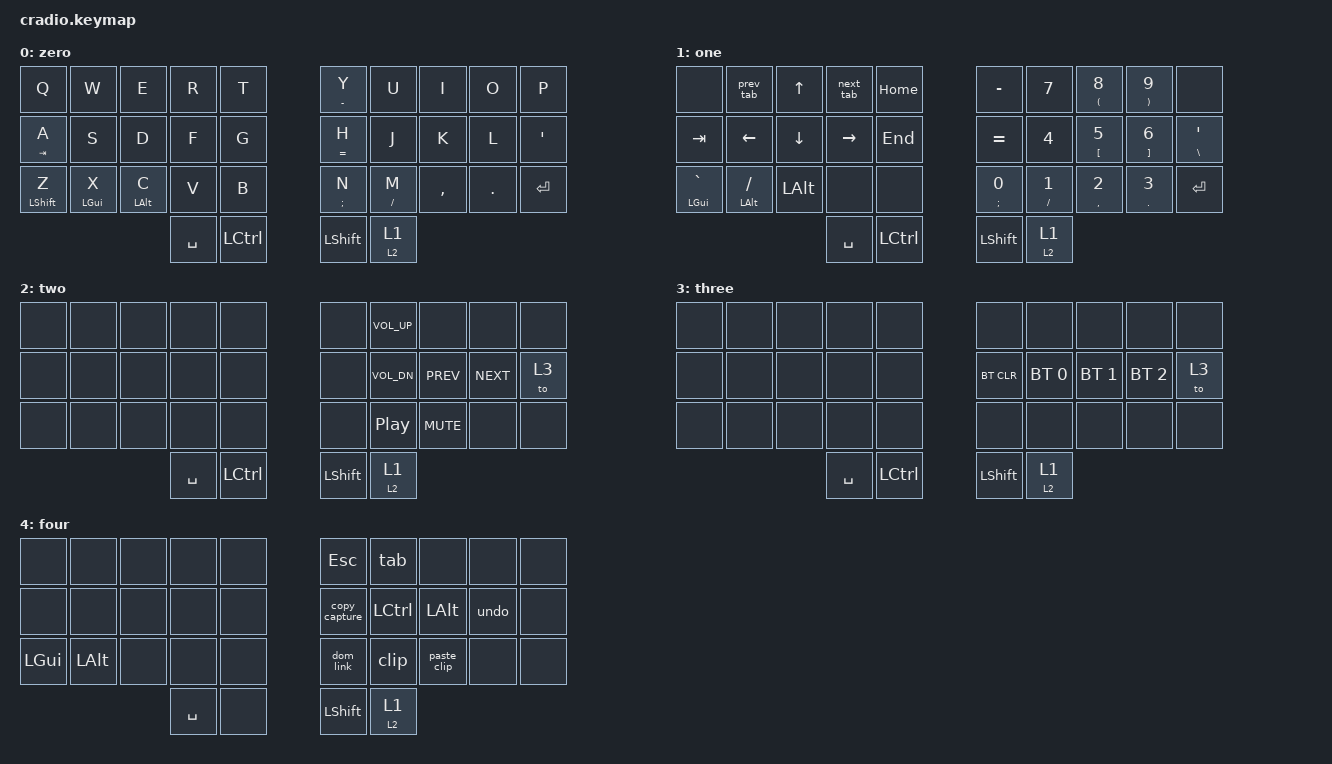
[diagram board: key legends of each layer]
/*
 * Copyright (c) 2020 The ZMK Contributors
 *
 * SPDX-License-Identifier: MIT
 */

#include <behaviors.dtsi>
#include <dt-bindings/zmk/keys.h>
#include <dt-bindings/zmk/bt.h>

&mt {
  //  flavor = "tap-preferred";
   // tapping_term_ms = <50>;
};

/ {    
        behaviors {
                to_kp: behavior_kp_to {
                compatible = "zmk,behavior-hold-tap";
                label = "kp_to";
                #binding-cells = <2>;
                flavor = "hold-preferred";
                tapping-term-ms = <750>;
                bindings = <&to>, <&kp>;
                };

                to_to: behavior_to_to {
                compatible = "zmk,behavior-hold-tap";
                label = "to_to";
                #binding-cells = <2>;
                flavor = "hold-preferred";
                tapping-term-ms = <750>;
                bindings = <&to>, <&to>;
                };

                tab: behavior_tab {
                compatible = "zmk,behavior-hold-tap";
                label = "tab";
                #binding-cells = <2>;
                flavor = "hold-preferred";
                tapping_term_ms = <500>;
                bindings = <&next_tab>, <&close_tab>;
                };

                clip: behavior_clip {
                compatible = "zmk,behavior-hold-tap";
                label = "clip";
                #binding-cells = <2>;
                flavor = "hold-preferred";
                tapping_term_ms = <100>;
                bindings = <&cut_clip>, <&copy_clip>;
                };
        };
    
        combos {
                compatible = "zmk,combos";
                combo_esc {
                        timeout-ms = <100>;
                        key-positions = <0 1>;
                        bindings = <&kp ESC>;
                };
                
                combo_bspc {
                        timeout-ms = <100>;
                        key-positions = <17 18>;
                        bindings = <&kp BSPC>;
                };
                
                combo_zero {
                        timeout-ms = <100>;
                        key-positions = <6 7>;
                        bindings = <&to 0>;
                };

                combo_five {
                        timeout-ms = <100>;
                        key-positions = <16 17>;
                        bindings = <&to 5>;
                };

                combo_four {
                        timeout-ms = <100>;
                        key-positions = <15 17>;
                        bindings = <&to 4>;
                };
        };

        macros {
                ZMK_MACRO(copy_capture,
                bindings = 
                <&macro_press &kp LSHIFT &kp LGUI>
                , <&macro_tap  &kp S>
                , <&macro_release &kp LSHIFT &kp LGUI>
                ;
                )

                ZMK_MACRO(next_tab,
                bindings = 
                <&macro_press &kp LCTL>
                , <&macro_tap  &kp TAB>
                , <&macro_release &kp LCTL>
                ;
                )

                ZMK_MACRO(prev_tab,
                bindings = 
                <&macro_press &kp LCTL &kp LSHIFT>
                , <&macro_tap  &kp TAB>
                , <&macro_release &kp LCTL &kp LSHIFT>
                ;
                )

                ZMK_MACRO(close_tab,
                bindings = 
                <&macro_press &kp LCTL>
                , <&macro_tap  &kp W>
                , <&macro_release &kp LCTL>
                ;
                )

                ZMK_MACRO(copy_clip,
                bindings = 
                <&macro_press &kp LCTL>
                , <&macro_tap  &kp C>
                , <&macro_release &kp LCTL>
                ;
                )

                ZMK_MACRO(cut_clip,
                bindings = 
                <&macro_press &kp LCTL>
                , <&macro_tap  &kp X>
                , <&macro_release &kp LCTL>
                ;
                )

                ZMK_MACRO(paste_clip,
                bindings = 
                <&macro_press &kp LCTL>
                , <&macro_tap  &kp V>
                , <&macro_release &kp LCTL>
                ;
                )

                ZMK_MACRO(dom_link,
                bindings = 
                <&macro_press &kp LCTL>
                , <&macro_tap  &kp L>
                , <&macro_release &kp LCTL>
                ;
                )

                ZMK_MACRO(undo,
                bindings = 
                <&macro_press &kp LCTL>
                , <&macro_tap  &kp Z>
                , <&macro_release &kp LCTL>
                ;
                )
        };

        keymap {
                compatible = "zmk,keymap";
                
       		zero {
	bindings = <
	&kp Q       &kp W       &kp E &kp R &kp T 			&mt MINUS Y &kp U  &kp I     &kp O   &kp P 
	&mt TAB A       &kp S       &kp D &kp F &kp G         	        &mt EQUAL H &kp J  &kp K     &kp L &kp QUOT
	&mt LSHIFT Z  &mt LGUI X  &mt LALT C &kp V &kp B	                &mt SEMI N &mt SLASH M  &kp CMMA  &kp DOT &kp RET
		&kp SPC  &kp LCTL                            			&kp LSHIFT  &to_to  2 1 
		>;
		};

       		one {
		bindings = <
        &none  &prev_tab   &kp UP    &next_tab      &kp HOME                           &kp MINUS  &kp N7  &mt LPAR N8   &mt RPAR N9  &none
        &kp TAB   &kp LEFT    &kp DOWN  &kp RIGHT      &kp END                              &kp EQUAL  &kp N4  &mt LBKT N5   &mt RBKT N6  &mt BSLH QUOT
        &mt LGUI GRAVE &mt LALT SLASH   &kp LALT  &none  &none           &mt SEMI N0     &mt SLASH N1  &mt COMMA N2  &mt DOT N3   &kp RET
                &kp SPC  &kp LCTL                                                                    &kp LSHIFT  &to_to 2 1
		>;
		};
		
		    two {
        bindings = <
        &none  &none  &none  &none  &none                    &none  &kp C_VOL_UP       &none       &none       &none
        &none  &none  &none  &none  &none                    &none  &kp C_VOL_DN       &kp C_PREV  &kp C_NEXT  &to 3
        &none  &none  &none  &none  &none                    &none  &kp C_PLAY_PAUSE   &kp C_MUTE  &none       &none
                &kp SPC  &kp LCTL                                     &kp LSHIFT  &to_to 2 1
		>;
		};	
		    three {
        bindings = <
        &none &none &none &none &none                       &none       &none         &none         &none         &none
        &none &none &none &none &none                       &bt BT_CLR  &bt BT_SEL 0  &bt BT_SEL 1  &bt BT_SEL 2  &to 3
        &none &none &none &none &none                       &none       &none         &none         &none         &none
                &kp SPC  &kp LCTL                                     &kp LSHIFT &to_to 2 1
		>;
		};	
                four{
        bindings = <
        &none &none &none &none &none                      &kp ESC        &tab      &none         &none  &none
        &none &none &none &none &none                      &copy_capture  &kp LCTL  &kp LALT      &undo  &none
        &kp LGUI &kp LALT &none &none &none                      &dom_link          &clip     &paste_clip   &none  &none
                &kp SPC  &none                                       &kp LSHIFT &to_to 2 1
                >;
                };
	};
        	five {
	bindings = <
	&kp Q       &kp W       &kp E &kp R &kp T 			&kp Y &kp U  &kp I     &kp O   &kp P 
	&kp A       &kp S       &kp D &kp F &kp G         	        &kp H &kp J  &kp K     &kp L &kp QUOT
	&kp Z  &kp X  &kp C &kp V &kp B	                &kp N &kp M  &kp CMMA  &kp DOT &kp RET
		&kp SPC  &kp LCTL                            			&kp LSHIFT  &to_to  2 1
		>;
		};
};

&kscan0 {
    input-gpios
    = <&pro_micro  7 (GPIO_ACTIVE_LOW | GPIO_PULL_UP)>
    , <&pro_micro 18 (GPIO_ACTIVE_LOW | GPIO_PULL_UP)>
    , <&pro_micro 19 (GPIO_ACTIVE_LOW | GPIO_PULL_UP)>
    , <&pro_micro 20 (GPIO_ACTIVE_LOW | GPIO_PULL_UP)>
    , <&pro_micro 21 (GPIO_ACTIVE_LOW | GPIO_PULL_UP)>
    , <&pro_micro 15 (GPIO_ACTIVE_LOW | GPIO_PULL_UP)>
    , <&pro_micro 14 (GPIO_ACTIVE_LOW | GPIO_PULL_UP)>
    , <&pro_micro 16 (GPIO_ACTIVE_LOW | GPIO_PULL_UP)>
    , <&pro_micro 10 (GPIO_ACTIVE_LOW | GPIO_PULL_UP)>
    , <&pro_micro  1 (GPIO_ACTIVE_LOW | GPIO_PULL_UP)>
    //, <&pro_micro  2 (GPIO_ACTIVE_LOW | GPIO_PULL_UP)>  // this is P0.17
    , <&gpio1      7 (GPIO_ACTIVE_LOW | GPIO_PULL_UP)>   // this is P1.07, can change the number if you want
    , <&pro_micro  3 (GPIO_ACTIVE_LOW | GPIO_PULL_UP)>
    , <&pro_micro  4 (GPIO_ACTIVE_LOW | GPIO_PULL_UP)>
    , <&pro_micro  5 (GPIO_ACTIVE_LOW | GPIO_PULL_UP)>
    , <&pro_micro  6 (GPIO_ACTIVE_LOW | GPIO_PULL_UP)>
    , <&pro_micro  8 (GPIO_ACTIVE_LOW | GPIO_PULL_UP)>
    , <&pro_micro  9 (GPIO_ACTIVE_LOW | GPIO_PULL_UP)>
    ;
};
